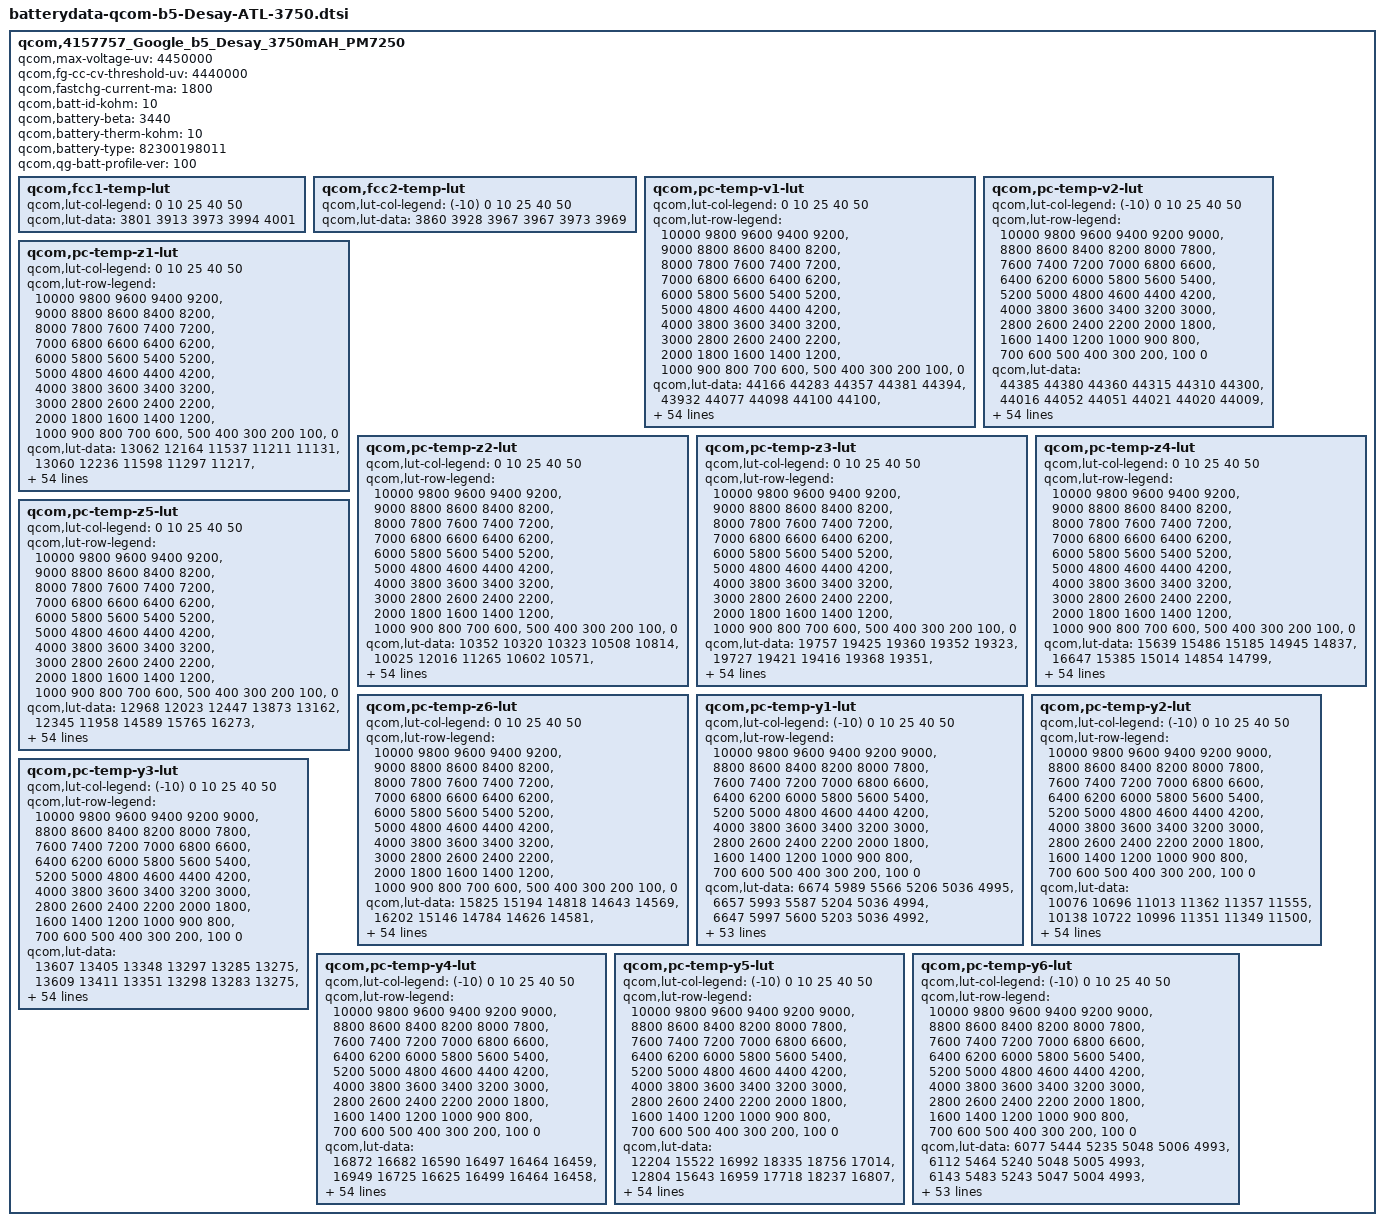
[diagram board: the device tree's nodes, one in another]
// SPDX-License-Identifier: GPL-2.0
qcom,4157757_Google_b5_Desay_3750mAH_PM7250 {
	/* Desay_3750mAH_PM7250_Sep5th2019 */
	qcom,max-voltage-uv = <4450000>;
	qcom,fg-cc-cv-threshold-uv = <4440000>;
	qcom,fastchg-current-ma = <1800>;
	qcom,batt-id-kohm = <10>;
	qcom,battery-beta = <3440>;
	qcom,battery-therm-kohm = <10>;
	qcom,battery-type = "82300198011";
	qcom,qg-batt-profile-ver = <100>;

	qcom,fcc1-temp-lut {
		qcom,lut-col-legend = <0 10 25 40 50>;
		qcom,lut-data = <3801 3913 3973 3994 4001>;
	};

	qcom,fcc2-temp-lut {
		qcom,lut-col-legend = <(-10) 0 10 25 40 50>;
		qcom,lut-data = <3860 3928 3967 3967 3973 3969>;
	};

	qcom,pc-temp-v1-lut {
		qcom,lut-col-legend = <0 10 25 40 50>;
		qcom,lut-row-legend = <10000 9800 9600 9400 9200>,
			<9000 8800 8600 8400 8200>,
			<8000 7800 7600 7400 7200>,
			<7000 6800 6600 6400 6200>,
			<6000 5800 5600 5400 5200>,
			<5000 4800 4600 4400 4200>,
			<4000 3800 3600 3400 3200>,
			<3000 2800 2600 2400 2200>,
			<2000 1800 1600 1400 1200>,
			<1000 900 800 700 600>,
			<500 400 300 200 100>,
			<0>;
		qcom,lut-data = <44166 44283 44357 44381 44394>,
			<43932 44077 44098 44100 44100>,
			<43697 43822 43870 43869 43864>,
			<43459 43586 43639 43651 43652>,
			<43219 43362 43409 43427 43436>,
			<42975 43126 43177 43197 43208>,
			<42732 42878 42935 42961 42973>,
			<42489 42629 42686 42717 42730>,
			<42247 42380 42437 42470 42483>,
			<42008 42134 42188 42220 42236>,
			<41773 41892 41942 41972 41989>,
			<41543 41654 41701 41730 41748>,
			<41318 41423 41465 41491 41512>,
			<41100 41198 41236 41260 41279>,
			<40894 40982 41014 41035 41052>,
			<40696 40779 40800 40818 40833>,
			<40493 40583 40593 40608 40621>,
			<40286 40389 40395 40406 40418>,
			<40097 40196 40209 40216 40226>,
			<39936 40012 40030 40034 40042>,
			<39786 39849 39857 39857 39863>,
			<39632 39682 39691 39688 39693>,
			<39478 39462 39493 39501 39507>,
			<39315 39201 39215 39257 39270>,
			<39129 38995 38977 39025 39038>,
			<38943 38830 38848 38869 38877>,
			<38787 38701 38750 38747 38749>,
			<38644 38612 38649 38635 38635>,
			<38537 38539 38551 38534 38531>,
			<38464 38467 38460 38440 38435>,
			<38407 38398 38377 38353 38346>,
			<38359 38334 38303 38274 38264>,
			<38318 38277 38239 38205 38191>,
			<38280 38225 38183 38143 38124>,
			<38248 38181 38134 38088 38062>,
			<38216 38142 38091 38039 38006>,
			<38185 38105 38048 37988 37946>,
			<38152 38073 38007 37932 37876>,
			<38106 38031 37958 37868 37797>,
			<38034 37950 37883 37788 37712>,
			<37942 37837 37776 37687 37616>,
			<37830 37718 37660 37574 37505>,
			<37694 37584 37526 37441 37371>,
			<37534 37421 37366 37286 37216>,
			<37376 37256 37200 37126 37058>,
			<37237 37141 37095 37028 36969>,
			<37199 37110 37063 37005 36945>,
			<37162 37089 37045 36990 36930>,
			<37128 37067 37027 36973 36913>,
			<37096 37035 36993 36935 36870>,
			<37047 36876 36814 36732 36645>,
			<36835 36460 36397 36301 36205>,
			<36374 35866 35820 35726 35629>,
			<35722 35018 35031 34942 34846>,
			<34695 33600 33805 33737 33630>,
			<30000 30000 30000 30000 30000>;
	};

	qcom,pc-temp-v2-lut {
		qcom,lut-col-legend = <(-10) 0 10 25 40 50>;
		qcom,lut-row-legend = <10000 9800 9600 9400 9200 9000>,
			<8800 8600 8400 8200 8000 7800>,
			<7600 7400 7200 7000 6800 6600>,
			<6400 6200 6000 5800 5600 5400>,
			<5200 5000 4800 4600 4400 4200>,
			<4000 3800 3600 3400 3200 3000>,
			<2800 2600 2400 2200 2000 1800>,
			<1600 1400 1200 1000 900 800>,
			<700 600 500 400 300 200>,
			<100 0>;
		qcom,lut-data = <44385 44380 44360 44315 44310 44300>,
			<44016 44052 44051 44021 44020 44009>,
			<43693 43758 43771 43750 43752 43740>,
			<43425 43507 43523 43505 43508 43496>,
			<43202 43290 43305 43283 43286 43275>,
			<42976 43064 43076 43052 43056 43046>,
			<42735 42820 42831 42808 42814 42807>,
			<42491 42572 42583 42562 42570 42565>,
			<42247 42323 42336 42314 42325 42321>,
			<42003 42073 42089 42067 42080 42076>,
			<41748 41830 41845 41824 41838 41835>,
			<41463 41593 41604 41585 41599 41596>,
			<41209 41363 41369 41352 41365 41362>,
			<41039 41139 41138 41121 41135 41134>,
			<40889 40920 40915 40897 40911 40912>,
			<40670 40714 40702 40681 40694 40697>,
			<40309 40515 40495 40474 40485 40488>,
			<39976 40290 40290 40274 40285 40287>,
			<39743 40017 40089 40084 40095 40095>,
			<39535 39748 39874 39893 39909 39909>,
			<39326 39514 39624 39703 39732 39735>,
			<39122 39298 39374 39504 39549 39555>,
			<38927 39102 39160 39274 39319 39328>,
			<38728 38921 38968 39024 39059 39070>,
			<38549 38757 38799 38832 38865 38875>,
			<38413 38609 38651 38688 38722 38731>,
			<38301 38471 38519 38564 38598 38606>,
			<38213 38337 38403 38452 38486 38493>,
			<38146 38211 38297 38351 38385 38392>,
			<38087 38109 38196 38256 38290 38296>,
			<38030 38022 38102 38169 38203 38209>,
			<37975 37952 38016 38090 38125 38130>,
			<37919 37904 37937 38019 38056 38058>,
			<37860 37863 37869 37952 37989 37988>,
			<37802 37820 37820 37889 37923 37918>,
			<37742 37776 37778 37828 37856 37844>,
			<37679 37729 37735 37761 37770 37748>,
			<37612 37679 37692 37691 37663 37623>,
			<37539 37620 37639 37615 37562 37509>,
			<37461 37540 37569 37529 37468 37413>,
			<37378 37437 37480 37441 37382 37324>,
			<37288 37334 37361 37353 37300 37238>,
			<37189 37215 37219 37221 37168 37109>,
			<37092 37072 37069 37093 37041 36982>,
			<36997 36906 36894 36928 36885 36831>,
			<36895 36788 36808 36884 36852 36803>,
			<36847 36754 36777 36871 36842 36791>,
			<36805 36717 36741 36855 36829 36776>,
			<36763 36677 36690 36828 36802 36752>,
			<36720 36631 36611 36762 36733 36666>,
			<36669 36538 36369 36523 36464 36377>,
			<36575 36271 35870 36045 35976 35873>,
			<36387 35688 35176 35397 35328 35223>,
			<36021 34813 34136 34511 34430 34317>,
			<35178 33550 32672 33199 33078 32962>,
			<34435 32158 27268 28016 28359 28215>;
	};

	qcom,pc-temp-z1-lut {
		qcom,lut-col-legend = <0 10 25 40 50>;
		qcom,lut-row-legend = <10000 9800 9600 9400 9200>,
			<9000 8800 8600 8400 8200>,
			<8000 7800 7600 7400 7200>,
			<7000 6800 6600 6400 6200>,
			<6000 5800 5600 5400 5200>,
			<5000 4800 4600 4400 4200>,
			<4000 3800 3600 3400 3200>,
			<3000 2800 2600 2400 2200>,
			<2000 1800 1600 1400 1200>,
			<1000 900 800 700 600>,
			<500 400 300 200 100>,
			<0>;
		qcom,lut-data = <13062 12164 11537 11211 11131>,
			<13060 12236 11598 11297 11217>,
			<13088 12242 11595 11304 11224>,
			<13103 12238 11586 11300 11225>,
			<13092 12230 11582 11298 11224>,
			<13074 12219 11578 11297 11225>,
			<13065 12200 11571 11295 11225>,
			<13061 12184 11563 11293 11225>,
			<13059 12171 11557 11292 11224>,
			<13060 12159 11552 11291 11223>,
			<13061 12154 11550 11291 11223>,
			<13061 12149 11550 11290 11223>,
			<13057 12148 11549 11290 11225>,
			<13050 12153 11550 11290 11226>,
			<13036 12158 11551 11291 11228>,
			<13019 12158 11552 11292 11229>,
			<13012 12157 11552 11294 11231>,
			<13013 12156 11554 11296 11233>,
			<13012 12153 11557 11299 11235>,
			<13008 12152 11562 11301 11236>,
			<13005 12159 11564 11303 11238>,
			<13006 12167 11566 11305 11241>,
			<13015 12169 11568 11307 11243>,
			<13021 12174 11571 11310 11246>,
			<13024 12179 11576 11314 11249>,
			<13026 12187 11583 11318 11252>,
			<13035 12195 11592 11322 11255>,
			<13056 12200 11600 11326 11259>,
			<13067 12205 11608 11330 11263>,
			<13075 12212 11612 11334 11266>,
			<13081 12223 11615 11337 11269>,
			<13076 12227 11617 11341 11271>,
			<13068 12226 11622 11344 11274>,
			<13064 12225 11629 11348 11278>,
			<13063 12231 11634 11352 11280>,
			<13066 12245 11639 11356 11283>,
			<13085 12253 11644 11359 11285>,
			<13121 12259 11650 11362 11288>,
			<13134 12268 11657 11366 11290>,
			<13133 12289 11663 11369 11293>,
			<13133 12317 11670 11372 11295>,
			<13145 12332 11675 11374 11297>,
			<13165 12344 11678 11376 11299>,
			<13184 12338 11682 11379 11301>,
			<13178 12333 11690 11383 11303>,
			<13199 12355 11700 11386 11305>,
			<13170 12340 11696 11386 11304>,
			<13198 12351 11703 11387 11305>,
			<13244 12338 11706 11387 11306>,
			<13250 12345 11703 11391 11307>,
			<13232 12352 11709 11396 11311>,
			<13212 12393 11720 11402 11317>,
			<13266 12404 11735 11412 11324>,
			<13282 12438 11759 11424 11335>,
			<13282 12438 11759 11424 11335>,
			<13282 12438 11759 11424 11335>;
	};

	qcom,pc-temp-z2-lut {
		qcom,lut-col-legend = <0 10 25 40 50>;
		qcom,lut-row-legend = <10000 9800 9600 9400 9200>,
			<9000 8800 8600 8400 8200>,
			<8000 7800 7600 7400 7200>,
			<7000 6800 6600 6400 6200>,
			<6000 5800 5600 5400 5200>,
			<5000 4800 4600 4400 4200>,
			<4000 3800 3600 3400 3200>,
			<3000 2800 2600 2400 2200>,
			<2000 1800 1600 1400 1200>,
			<1000 900 800 700 600>,
			<500 400 300 200 100>,
			<0>;
		qcom,lut-data = <10352 10320 10323 10508 10814>,
			<10025 12016 11265 10602 10571>,
			<10025 10344 11046 11287 10950>,
			<10037 10199 10451 11310 11426>,
			<10038 10169 10400 11211 11290>,
			<10039 10141 10374 11017 11109>,
			<10041 10112 10344 10949 11078>,
			<10043 10096 10319 10930 11101>,
			<10043 10091 10318 10888 11108>,
			<10037 10088 10352 10718 10868>,
			<10025 10097 10391 10582 10613>,
			<10016 10131 10504 10711 10763>,
			<10006 10159 10632 10955 11118>,
			<10003 10176 10644 10999 11131>,
			<10015 10198 10636 10975 10742>,
			<10033 10296 10641 10964 10528>,
			<10042 10434 10671 10994 10542>,
			<10048 10441 10695 11020 10562>,
			<10057 10352 10625 10891 10581>,
			<10077 10302 10518 10635 10609>,
			<10101 10300 10504 10589 10631>,
			<10112 10302 10504 10632 10646>,
			<10119 10310 10500 10666 10670>,
			<10126 10327 10480 10660 10761>,
			<10135 10330 10465 10644 10851>,
			<10144 10310 10484 10694 10825>,
			<10153 10293 10515 10806 10739>,
			<10162 10291 10522 10808 10681>,
			<10170 10293 10524 10667 10569>,
			<10176 10295 10516 10578 10496>,
			<10183 10301 10479 10567 10482>,
			<10190 10306 10448 10565 10479>,
			<10197 10311 10456 10578 10494>,
			<10203 10316 10478 10607 10522>,
			<10209 10324 10495 10643 10566>,
			<10214 10335 10517 10693 10667>,
			<10221 10343 10536 10741 10769>,
			<10230 10348 10548 10777 10862>,
			<10242 10355 10560 10811 10932>,
			<10258 10372 10585 10854 10940>,
			<10277 10391 10618 10904 10935>,
			<10296 10397 10625 10915 10916>,
			<10320 10398 10620 10902 10841>,
			<10374 10411 10622 10891 10816>,
			<10400 10495 10646 10871 10829>,
			<10696 10700 10740 10835 10867>,
			<10622 10740 10723 10810 10840>,
			<10516 11093 10721 10793 10808>,
			<10452 11785 10721 10790 10828>,
			<10388 11976 10739 10857 10947>,
			<10368 11692 10927 10799 10746>,
			<10329 11515 11056 10697 10585>,
			<10130 11188 11035 10615 10523>,
			<10142 10535 10919 10537 10472>,
			<10142 10535 10919 10537 10472>,
			<10142 10535 10919 10537 10472>;
	};

	qcom,pc-temp-z3-lut {
		qcom,lut-col-legend = <0 10 25 40 50>;
		qcom,lut-row-legend = <10000 9800 9600 9400 9200>,
			<9000 8800 8600 8400 8200>,
			<8000 7800 7600 7400 7200>,
			<7000 6800 6600 6400 6200>,
			<6000 5800 5600 5400 5200>,
			<5000 4800 4600 4400 4200>,
			<4000 3800 3600 3400 3200>,
			<3000 2800 2600 2400 2200>,
			<2000 1800 1600 1400 1200>,
			<1000 900 800 700 600>,
			<500 400 300 200 100>,
			<0>;
		qcom,lut-data = <19757 19425 19360 19352 19323>,
			<19727 19421 19416 19368 19351>,
			<19846 19648 19442 19380 19353>,
			<19935 19689 19509 19424 19381>,
			<19949 19698 19518 19442 19399>,
			<19953 19703 19521 19448 19405>,
			<19946 19707 19520 19446 19405>,
			<19922 19708 19517 19437 19405>,
			<19904 19702 19510 19427 19403>,
			<19906 19692 19494 19411 19390>,
			<19913 19680 19484 19399 19375>,
			<19918 19664 19492 19404 19373>,
			<19927 19649 19502 19415 19373>,
			<19931 19632 19496 19414 19370>,
			<19921 19622 19478 19403 19357>,
			<19906 19630 19469 19394 19348>,
			<19899 19645 19467 19392 19344>,
			<19891 19642 19464 19389 19341>,
			<19882 19612 19453 19379 19340>,
			<19865 19597 19440 19365 19339>,
			<19848 19598 19440 19361 19339>,
			<19844 19600 19443 19364 19339>,
			<19846 19611 19446 19365 19338>,
			<19850 19637 19451 19358 19337>,
			<19855 19644 19455 19351 19337>,
			<19859 19634 19444 19367 19353>,
			<19860 19623 19426 19403 19385>,
			<19860 19614 19430 19413 19392>,
			<19858 19605 19456 19411 19383>,
			<19851 19605 19472 19407 19374>,
			<19842 19612 19477 19402 19368>,
			<19834 19616 19478 19396 19362>,
			<19827 19617 19474 19389 19357>,
			<19819 19618 19467 19382 19352>,
			<19812 19617 19462 19377 19348>,
			<19806 19614 19458 19373 19345>,
			<19800 19610 19454 19371 19343>,
			<19794 19604 19453 19371 19345>,
			<19786 19599 19451 19371 19347>,
			<19777 19595 19447 19370 19348>,
			<19766 19591 19442 19368 19347>,
			<19753 19585 19436 19367 19346>,
			<19735 19577 19431 19363 19342>,
			<19710 19567 19429 19362 19341>,
			<19577 19542 19425 19361 19343>,
			<19438 19490 19400 19348 19328>,
			<19304 19474 19401 19344 19325>,
			<19282 19404 19394 19339 19325>,
			<19280 19317 19389 19338 19323>,
			<19279 19296 19387 19334 19317>,
			<19277 19309 19366 19344 19338>,
			<19278 19314 19345 19355 19347>,
			<19282 19314 19339 19360 19349>,
			<19320 19489 19343 19362 19342>,
			<19320 19489 19343 19362 19342>,
			<19320 19489 19343 19362 19342>;
	};

	qcom,pc-temp-z4-lut {
		qcom,lut-col-legend = <0 10 25 40 50>;
		qcom,lut-row-legend = <10000 9800 9600 9400 9200>,
			<9000 8800 8600 8400 8200>,
			<8000 7800 7600 7400 7200>,
			<7000 6800 6600 6400 6200>,
			<6000 5800 5600 5400 5200>,
			<5000 4800 4600 4400 4200>,
			<4000 3800 3600 3400 3200>,
			<3000 2800 2600 2400 2200>,
			<2000 1800 1600 1400 1200>,
			<1000 900 800 700 600>,
			<500 400 300 200 100>,
			<0>;
		qcom,lut-data = <15639 15486 15185 14945 14837>,
			<16647 15385 15014 14854 14799>,
			<16403 15501 14912 14787 14754>,
			<16089 15459 15047 14843 14781>,
			<15870 15264 14991 14831 14792>,
			<15675 15140 14912 14785 14760>,
			<15534 15057 14867 14759 14736>,
			<15433 14995 14832 14741 14715>,
			<15346 14948 14809 14732 14706>,
			<15261 14911 14795 14737 14713>,
			<15181 14877 14780 14743 14721>,
			<15112 14847 14748 14725 14713>,
			<15048 14833 14720 14695 14697>,
			<14993 14828 14719 14688 14693>,
			<14945 14822 14722 14687 14699>,
			<14906 14792 14722 14685 14701>,
			<14890 14749 14714 14678 14695>,
			<14882 14747 14706 14671 14688>,
			<14875 14773 14711 14674 14681>,
			<14865 14787 14720 14685 14674>,
			<14853 14774 14721 14689 14673>,
			<14840 14758 14721 14692 14677>,
			<14820 14777 14728 14697 14685>,
			<14812 14835 14814 14771 14743>,
			<14840 14873 14884 14846 14805>,
			<14880 14905 14883 14829 14790>,
			<14905 14924 14879 14777 14739>,
			<14935 14914 14863 14748 14719>,
			<14947 14891 14815 14732 14713>,
			<14940 14869 14780 14721 14708>,
			<14928 14847 14760 14712 14701>,
			<14916 14828 14747 14706 14694>,
			<14899 14814 14742 14701 14687>,
			<14882 14802 14740 14698 14681>,
			<14867 14795 14739 14698 14680>,
			<14853 14789 14739 14699 14682>,
			<14837 14784 14739 14701 14685>,
			<14822 14778 14740 14708 14696>,
			<14808 14774 14743 14716 14707>,
			<14795 14772 14746 14719 14707>,
			<14784 14770 14750 14720 14703>,
			<14771 14763 14748 14719 14699>,
			<14758 14743 14732 14709 14692>,
			<14741 14728 14722 14705 14691>,
			<14785 14709 14713 14702 14692>,
			<14853 14683 14682 14680 14675>,
			<14996 14692 14670 14675 14668>,
			<15014 14757 14662 14660 14650>,
			<15009 14847 14652 14643 14635>,
			<15004 14865 14650 14644 14638>,
			<14999 14857 14688 14653 14636>,
			<15003 14864 14720 14649 14633>,
			<15025 14876 14729 14644 14632>,
			<15015 14703 14729 14642 14638>,
			<15015 14703 14729 14642 14638>,
			<15015 14703 14729 14642 14638>;
	};

	qcom,pc-temp-z5-lut {
		qcom,lut-col-legend = <0 10 25 40 50>;
		qcom,lut-row-legend = <10000 9800 9600 9400 9200>,
			<9000 8800 8600 8400 8200>,
			<8000 7800 7600 7400 7200>,
			<7000 6800 6600 6400 6200>,
			<6000 5800 5600 5400 5200>,
			<5000 4800 4600 4400 4200>,
			<4000 3800 3600 3400 3200>,
			<3000 2800 2600 2400 2200>,
			<2000 1800 1600 1400 1200>,
			<1000 900 800 700 600>,
			<500 400 300 200 100>,
			<0>;
		qcom,lut-data = <12968 12023 12447 13873 13162>,
			<12345 11958 14589 15765 16273>,
			<12974 14415 16140 17362 17820>,
			<13597 14919 16270 17877 18335>,
			<13932 15276 16688 18411 18110>,
			<14183 15699 17094 19680 19215>,
			<14351 16216 17530 20303 20468>,
			<14451 16681 17968 20664 22319>,
			<14592 17020 18188 20713 23102>,
			<14947 17367 18274 19475 21255>,
			<15528 17981 18432 18371 19249>,
			<16192 18817 21047 20691 19842>,
			<17077 19082 24258 24989 21496>,
			<18042 19005 23944 25496 21523>,
			<18997 18947 22318 24141 19427>,
			<19977 20520 21913 23534 18182>,
			<20982 23291 22886 24902 18258>,
			<22085 23434 23735 26324 18571>,
			<22762 21584 22973 24754 19267>,
			<22501 20616 21751 21323 20410>,
			<22042 22279 22426 20921 21078>,
			<23087 25591 24458 22039 21594>,
			<27100 31519 25610 22521 21616>,
			<31307 40467 26065 19709 18897>,
			<35465 42580 26084 16726 15878>,
			<39100 36316 22963 17180 16651>,
			<40628 29846 18048 18694 19163>,
			<40842 26487 17669 19716 20211>,
			<39943 23903 19501 20581 20347>,
			<37932 23741 21475 21523 20330>,
			<35923 24852 24281 22689 20802>,
			<34782 26123 27096 23914 21651>,
			<33732 28095 28889 24978 22584>,
			<32866 30303 30365 25956 23880>,
			<32368 31995 31438 26830 25018>,
			<32324 33449 32524 27864 26248>,
			<32730 33717 32959 28349 26845>,
			<33387 33133 32742 27942 26478>,
			<34232 32708 32265 27191 25783>,
			<35643 32862 30733 25989 24978>,
			<36665 33090 27915 23977 23810>,
			<35896 32737 26595 23033 22835>,
			<34298 31438 26070 22572 22057>,
			<33123 30963 25853 22182 21399>,
			<26641 30387 25646 21413 20718>,
			<19028 28698 25046 21574 19399>,
			<12237 23877 26575 21147 19410>,
			<11614 16410 25301 21819 21994>,
			<11571 12483 24631 24825 25933>,
			<11548 11904 24449 23281 23662>,
			<11541 12201 17750 20855 26002>,
			<11596 12165 14466 21917 27686>,
			<11518 12064 13895 22968 27956>,
			<11756 23977 13859 23266 21994>,
			<11756 23977 13859 23266 21994>,
			<11756 23977 13859 23266 21994>;
	};

	qcom,pc-temp-z6-lut {
		qcom,lut-col-legend = <0 10 25 40 50>;
		qcom,lut-row-legend = <10000 9800 9600 9400 9200>,
			<9000 8800 8600 8400 8200>,
			<8000 7800 7600 7400 7200>,
			<7000 6800 6600 6400 6200>,
			<6000 5800 5600 5400 5200>,
			<5000 4800 4600 4400 4200>,
			<4000 3800 3600 3400 3200>,
			<3000 2800 2600 2400 2200>,
			<2000 1800 1600 1400 1200>,
			<1000 900 800 700 600>,
			<500 400 300 200 100>,
			<0>;
		qcom,lut-data = <15825 15194 14818 14643 14569>,
			<16202 15146 14784 14626 14581>,
			<16127 15293 14752 14606 14564>,
			<16020 15284 14839 14654 14592>,
			<15921 15196 14817 14655 14604>,
			<15817 15138 14785 14641 14595>,
			<15733 15098 14764 14629 14587>,
			<15665 15064 14746 14616 14579>,
			<15608 15035 14729 14606 14572>,
			<15562 15010 14714 14600 14567>,
			<15524 14985 14702 14595 14563>,
			<15490 14962 14694 14590 14558>,
			<15461 14946 14687 14584 14553>,
			<15433 14936 14681 14578 14548>,
			<15402 14927 14674 14572 14543>,
			<15374 14917 14669 14567 14539>,
			<15360 14908 14664 14563 14534>,
			<15353 14903 14660 14559 14530>,
			<15346 14900 14656 14555 14526>,
			<15335 14897 14654 14552 14523>,
			<15323 14893 14654 14552 14523>,
			<15318 14890 14656 14554 14525>,
			<15314 14904 14662 14558 14528>,
			<15313 14945 14703 14588 14554>,
			<15330 14966 14736 14617 14582>,
			<15354 14977 14732 14618 14583>,
			<15367 14982 14724 14615 14580>,
			<15382 14974 14718 14611 14576>,
			<15388 14962 14713 14603 14569>,
			<15383 14955 14708 14596 14562>,
			<15375 14950 14703 14590 14556>,
			<15367 14946 14699 14585 14550>,
			<15357 14942 14695 14579 14545>,
			<15349 14939 14691 14575 14539>,
			<15342 14937 14689 14572 14537>,
			<15336 14935 14687 14571 14537>,
			<15330 14933 14687 14570 14537>,
			<15326 14931 14688 14573 14542>,
			<15322 14930 14689 14578 14548>,
			<15321 14932 14689 14578 14549>,
			<15319 14935 14689 14578 14547>,
			<15315 14933 14688 14578 14545>,
			<15310 14925 14680 14572 14540>,
			<15302 14918 14676 14570 14540>,
			<15267 14905 14672 14569 14542>,
			<15232 14872 14649 14553 14527>,
			<15228 14868 14645 14549 14522>,
			<15227 14861 14638 14540 14514>,
			<15227 14857 14632 14532 14506>,
			<15227 14857 14631 14531 14505>,
			<15233 14865 14640 14541 14516>,
			<15246 14877 14646 14546 14521>,
			<15272 14891 14650 14549 14524>,
			<15306 14921 14658 14552 14525>,
			<15306 14921 14658 14552 14525>,
			<15306 14921 14658 14552 14525>;
	};

	qcom,pc-temp-y1-lut {
		qcom,lut-col-legend = <(-10) 0 10 25 40 50>;
		qcom,lut-row-legend = <10000 9800 9600 9400 9200 9000>,
			<8800 8600 8400 8200 8000 7800>,
			<7600 7400 7200 7000 6800 6600>,
			<6400 6200 6000 5800 5600 5400>,
			<5200 5000 4800 4600 4400 4200>,
			<4000 3800 3600 3400 3200 3000>,
			<2800 2600 2400 2200 2000 1800>,
			<1600 1400 1200 1000 900 800>,
			<700 600 500 400 300 200>,
			<100 0>;
		qcom,lut-data = <6674 5989 5566 5206 5036 4995>,
			<6657 5993 5587 5204 5036 4994>,
			<6647 5997 5600 5203 5036 4992>,
			<6641 6002 5608 5201 5035 4990>,
			<6639 6004 5612 5199 5034 4988>,
			<6639 6003 5612 5197 5033 4988>,
			<6644 6000 5601 5196 5031 4988>,
			<6650 5996 5592 5194 5030 4988>,
			<6656 5989 5593 5191 5029 4988>,
			<6669 5980 5595 5187 5028 4986>,
			<6672 5979 5593 5185 5028 4986>,
			<6666 5985 5586 5182 5027 4987>,
			<6656 5992 5579 5181 5026 4988>,
			<6648 6011 5574 5182 5026 4988>,
			<6640 6031 5571 5183 5026 4988>,
			<6640 6025 5574 5182 5027 4989>,
			<6650 6003 5580 5182 5028 4989>,
			<6658 5995 5582 5182 5029 4990>,
			<6656 6000 5580 5184 5030 4991>,
			<6652 6005 5579 5186 5031 4991>,
			<6653 6008 5581 5189 5032 4992>,
			<6653 6010 5584 5191 5032 4992>,
			<6653 6014 5585 5194 5033 4993>,
			<6651 6022 5588 5197 5034 4995>,
			<6646 6030 5591 5200 5036 4996>,
			<6645 6035 5593 5203 5038 4998>,
			<6649 6037 5595 5207 5040 4999>,
			<6656 6034 5597 5210 5041 5001>,
			<6678 6030 5599 5214 5043 5002>,
			<6701 6029 5599 5218 5045 5003>,
			<6701 6026 5600 5223 5049 5005>,
			<6689 6024 5601 5227 5052 5006>,
			<6678 6026 5603 5230 5054 5009>,
			<6648 6031 5607 5233 5056 5011>,
			<6630 6033 5619 5237 5058 5013>,
			<6636 6035 5635 5242 5060 5015>,
			<6647 6036 5635 5246 5062 5017>,
			<6657 6037 5628 5249 5064 5018>,
			<6668 6038 5626 5251 5066 5019>,
			<6675 6050 5631 5255 5067 5020>,
			<6686 6070 5638 5256 5068 5021>,
			<6695 6057 5648 5252 5071 5022>,
			<6689 6072 5634 5267 5072 5024>,
			<6703 6077 5661 5267 5073 5025>,
			<6726 6086 5656 5270 5076 5027>,
			<6720 6063 5676 5265 5077 5027>,
			<6752 6080 5669 5269 5077 5028>,
			<6735 6093 5659 5273 5079 5028>,
			<6782 6131 5663 5274 5080 5029>,
			<6823 6112 5663 5278 5080 5030>,
			<6818 6144 5679 5284 5080 5030>,
			<6955 6223 5710 5295 5085 5034>,
			<7106 6341 5799 5308 5091 5039>,
			<7298 6589 5946 5324 5098 5045>,
			<7298 6589 5946 5324 5098 5045>,
			<7298 6589 5946 5324 5098 5045>;
	};

	qcom,pc-temp-y2-lut {
		qcom,lut-col-legend = <(-10) 0 10 25 40 50>;
		qcom,lut-row-legend = <10000 9800 9600 9400 9200 9000>,
			<8800 8600 8400 8200 8000 7800>,
			<7600 7400 7200 7000 6800 6600>,
			<6400 6200 6000 5800 5600 5400>,
			<5200 5000 4800 4600 4400 4200>,
			<4000 3800 3600 3400 3200 3000>,
			<2800 2600 2400 2200 2000 1800>,
			<1600 1400 1200 1000 900 800>,
			<700 600 500 400 300 200>,
			<100 0>;
		qcom,lut-data = <10076 10696 11013 11362 11357 11555>,
			<10138 10722 10996 11351 11349 11500>,
			<10210 10735 10977 11327 11336 11412>,
			<10281 10738 10954 11295 11321 11317>,
			<10340 10735 10930 11260 11306 11244>,
			<10374 10728 10903 11227 11291 11216>,
			<10393 10710 10870 11185 11263 11207>,
			<10405 10692 10841 11150 11236 11200>,
			<10410 10684 10819 11136 11209 11177>,
			<10411 10679 10803 11124 11176 11139>,
			<10400 10679 10798 11107 11162 11114>,
			<10280 10688 10796 11083 11149 11078>,
			<10183 10702 10796 11068 11145 11065>,
			<10293 10747 10812 11061 11163 11117>,
			<10504 10799 10841 11057 11183 11174>,
			<10517 10814 10879 11065 11190 11192>,
			<10317 10822 10930 11088 11201 11208>,
			<10194 10836 10974 11121 11215 11211>,
			<10198 10872 11019 11181 11238 11208>,
			<10200 10901 11040 11236 11275 11209>,
			<10201 10907 11037 11284 11395 11294>,
			<10199 10911 11034 11316 11508 11397>,
			<10194 10919 11041 11312 11492 11404>,
			<9978 10935 11057 11298 11440 11380>,
			<9713 10946 11073 11298 11429 11386>,
			<9679 10954 11091 11327 11452 11422>,
			<9673 10960 11104 11348 11478 11455>,
			<9670 10960 11111 11349 11499 11486>,
			<9668 10956 11116 11348 11521 11512>,
			<9667 10959 11122 11354 11540 11537>,
			<9665 11004 11128 11370 11558 11608>,
			<9664 11041 11130 11376 11592 11645>,
			<9663 11002 11125 11376 11690 11667>,
			<9661 10911 11118 11372 11756 11692>,
			<9660 10730 11107 11357 11719 11740>,
			<9659 10406 11089 11336 11650 11795>,
			<9659 10256 11065 11332 11599 11768>,
			<9658 10206 11027 11332 11548 11629>,
			<9658 10157 10981 11333 11520 11563>,
			<9657 9981 10920 11338 11497 11566>,
			<9657 9704 10852 11337 11491 11561>,
			<9657 9679 10781 11324 11499 11533>,
			<9657 9672 10693 11322 11522 11587>,
			<9657 9673 10716 11320 11577 11547>,
			<9656 9666 10598 11276 11504 11536>,
			<9656 9661 10231 11196 11399 11353>,
			<9655 9659 10131 11192 11406 11291>,
			<9655 9657 9989 11197 11332 11264>,
			<9654 9656 9781 11177 11292 11235>,
			<9653 9654 9698 11141 11292 11205>,
			<9650 9652 9665 11105 11269 11204>,
			<9649 9649 9655 11056 11237 11162>,
			<9648 9648 9650 10957 11164 11079>,
			<9647 9647 9649 10848 11057 10918>,
			<9647 9647 9649 10848 11057 10918>,
			<9647 9647 9649 10848 11057 10918>;
	};

	qcom,pc-temp-y3-lut {
		qcom,lut-col-legend = <(-10) 0 10 25 40 50>;
		qcom,lut-row-legend = <10000 9800 9600 9400 9200 9000>,
			<8800 8600 8400 8200 8000 7800>,
			<7600 7400 7200 7000 6800 6600>,
			<6400 6200 6000 5800 5600 5400>,
			<5200 5000 4800 4600 4400 4200>,
			<4000 3800 3600 3400 3200 3000>,
			<2800 2600 2400 2200 2000 1800>,
			<1600 1400 1200 1000 900 800>,
			<700 600 500 400 300 200>,
			<100 0>;
		qcom,lut-data = <13607 13405 13348 13297 13285 13275>,
			<13609 13411 13351 13298 13283 13275>,
			<13612 13418 13354 13297 13281 13275>,
			<13617 13425 13356 13297 13280 13275>,
			<13620 13430 13359 13296 13279 13276>,
			<13621 13433 13360 13295 13279 13276>,
			<13621 13436 13361 13295 13280 13277>,
			<13621 13437 13361 13294 13281 13278>,
			<13618 13437 13363 13294 13283 13279>,
			<13609 13437 13366 13295 13286 13279>,
			<13602 13435 13367 13298 13287 13280>,
			<13582 13431 13367 13304 13290 13280>,
			<13567 13429 13368 13307 13291 13281>,
			<13553 13429 13367 13307 13291 13285>,
			<13525 13429 13366 13307 13292 13288>,
			<13517 13427 13364 13308 13291 13288>,
			<13519 13419 13359 13312 13289 13288>,
			<13520 13413 13359 13312 13289 13287>,
			<13516 13409 13361 13311 13292 13285>,
			<13508 13406 13362 13310 13294 13284>,
			<13500 13399 13357 13312 13295 13287>,
			<13490 13392 13348 13313 13296 13290>,
			<13483 13386 13344 13311 13293 13288>,
			<13480 13382 13340 13303 13285 13280>,
			<13477 13378 13337 13298 13282 13277>,
			<13475 13375 13334 13296 13282 13275>,
			<13476 13372 13332 13295 13281 13275>,
			<13483 13367 13332 13296 13281 13275>,
			<13505 13362 13332 13296 13281 13275>,
			<13536 13355 13332 13296 13280 13275>,
			<13569 13342 13330 13296 13279 13275>,
			<13611 13333 13329 13297 13279 13275>,
			<13659 13339 13329 13297 13280 13275>,
			<13718 13350 13329 13297 13281 13275>,
			<13786 13359 13329 13298 13282 13276>,
			<13865 13367 13330 13298 13282 13277>,
			<13951 13377 13332 13298 13282 13277>,
			<14037 13393 13336 13297 13281 13275>,
			<14126 13413 13339 13296 13280 13275>,
			<14204 13433 13343 13294 13278 13274>,
			<14268 13457 13345 13292 13278 13274>,
			<14321 13494 13347 13294 13280 13274>,
			<14365 13533 13348 13293 13277 13274>,
			<14407 13508 13342 13292 13277 13275>,
			<14348 13582 13349 13294 13276 13273>,
			<14514 13724 13353 13296 13278 13276>,
			<14622 13837 13368 13299 13280 13277>,
			<14761 13983 13387 13303 13284 13280>,
			<14961 14207 13419 13306 13287 13284>,
			<15338 14564 13497 13310 13291 13284>,
			<16612 15272 13658 13310 13287 13282>,
			<20476 18407 14204 13312 13289 13281>,
			<31819 31860 16531 13318 13291 13285>,
			<65535 65535 30317 13328 13294 13287>,
			<65535 65535 30317 13328 13294 13287>,
			<65535 65535 30317 13328 13294 13287>;
	};

	qcom,pc-temp-y4-lut {
		qcom,lut-col-legend = <(-10) 0 10 25 40 50>;
		qcom,lut-row-legend = <10000 9800 9600 9400 9200 9000>,
			<8800 8600 8400 8200 8000 7800>,
			<7600 7400 7200 7000 6800 6600>,
			<6400 6200 6000 5800 5600 5400>,
			<5200 5000 4800 4600 4400 4200>,
			<4000 3800 3600 3400 3200 3000>,
			<2800 2600 2400 2200 2000 1800>,
			<1600 1400 1200 1000 900 800>,
			<700 600 500 400 300 200>,
			<100 0>;
		qcom,lut-data = <16872 16682 16590 16497 16464 16459>,
			<16949 16725 16625 16499 16464 16458>,
			<17093 16796 16657 16500 16465 16457>,
			<17252 16871 16683 16502 16466 16455>,
			<17377 16928 16699 16504 16466 16454>,
			<17419 16943 16702 16506 16467 16453>,
			<17412 16938 16692 16510 16467 16453>,
			<17403 16931 16682 16515 16467 16452>,
			<17398 16928 16677 16519 16467 16453>,
			<17395 16926 16674 16523 16467 16456>,
			<17396 16928 16675 16523 16468 16459>,
			<17414 16947 16683 16521 16469 16463>,
			<17435 16971 16693 16521 16472 16465>,
			<17483 16994 16709 16531 16477 16464>,
			<17562 17019 16731 16546 16484 16464>,
			<17552 17048 16772 16558 16494 16467>,
			<17354 17083 16823 16570 16507 16476>,
			<17182 17086 16834 16591 16519 16487>,
			<17123 16982 16830 16630 16531 16501>,
			<17080 16871 16821 16655 16546 16517>,
			<17031 16822 16768 16662 16577 16540>,
			<16979 16785 16693 16666 16603 16557>,
			<16935 16752 16647 16631 16575 16538>,
			<16894 16722 16610 16538 16505 16486>,
			<16865 16696 16590 16503 16477 16466>,
			<16855 16674 16577 16496 16469 16461>,
			<16849 16654 16570 16493 16466 16459>,
			<16847 16626 16567 16495 16468 16461>,
			<16847 16597 16564 16499 16473 16464>,
			<16849 16592 16560 16504 16479 16469>,
			<16852 16605 16554 16510 16488 16476>,
			<16856 16618 16547 16516 16498 16484>,
			<16862 16621 16533 16525 16508 16495>,
			<16872 16625 16524 16531 16516 16503>,
			<16880 16641 16530 16531 16521 16506>,
			<16885 16681 16544 16531 16525 16508>,
			<16890 16714 16561 16528 16517 16503>,
			<16893 16740 16584 16512 16488 16478>,
			<16896 16763 16607 16498 16469 16463>,
			<16897 16785 16629 16486 16462 16457>,
			<16892 16803 16639 16484 16461 16456>,
			<16886 16796 16643 16495 16466 16461>,
			<16882 16780 16628 16489 16461 16452>,
			<16873 16736 16591 16488 16463 16452>,
			<16840 16721 16591 16472 16448 16436>,
			<16848 16727 16636 16484 16457 16446>,
			<16858 16728 16654 16494 16465 16456>,
			<16866 16750 16686 16508 16472 16464>,
			<16880 16777 16739 16527 16486 16481>,
			<16901 16811 16794 16542 16496 16487>,
			<17006 16858 16815 16533 16469 16459>,
			<17485 17156 16839 16533 16462 16452>,
			<18953 19855 17156 16557 16473 16465>,
			<26066 65535 25613 16622 16514 16504>,
			<26066 65535 25613 16622 16514 16504>,
			<26066 65535 25613 16622 16514 16504>;
	};

	qcom,pc-temp-y5-lut {
		qcom,lut-col-legend = <(-10) 0 10 25 40 50>;
		qcom,lut-row-legend = <10000 9800 9600 9400 9200 9000>,
			<8800 8600 8400 8200 8000 7800>,
			<7600 7400 7200 7000 6800 6600>,
			<6400 6200 6000 5800 5600 5400>,
			<5200 5000 4800 4600 4400 4200>,
			<4000 3800 3600 3400 3200 3000>,
			<2800 2600 2400 2200 2000 1800>,
			<1600 1400 1200 1000 900 800>,
			<700 600 500 400 300 200>,
			<100 0>;
		qcom,lut-data = <12204 15522 16992 18335 18756 17014>,
			<12804 15643 16959 17718 18237 16807>,
			<13380 15721 16877 16852 17189 16578>,
			<13920 15765 16758 15916 16012 16374>,
			<14413 15782 16617 15089 15110 16243>,
			<14849 15780 16461 14526 14846 16231>,
			<15285 15749 16253 13994 14830 16318>,
			<15617 15691 16070 13592 14814 16385>,
			<15721 15542 15957 13393 15148 16258>,
			<15717 15279 15836 13265 15741 15954>,
			<15639 15056 15618 13422 15939 15608>,
			<14964 14813 15162 14165 16312 15157>,
			<14417 14690 14771 14494 16322 15020>,
			<15123 14686 14455 14008 15854 16090>,
			<16443 14694 14266 13527 15245 17150>,
			<16669 15252 14295 13547 14511 16844>,
			<16548 16911 14417 13635 13773 15931>,
			<16575 17899 14953 13667 13639 15046>,
			<16505 18518 17243 13615 13709 14039>,
			<16335 18929 18920 13680 13844 13605>,
			<16286 19031 19515 16240 14605 14268>,
			<16273 19101 19871 19189 15731 15375>,
			<16118 19239 19988 19355 16731 16440>,
			<14779 19472 20060 19228 17700 17521>,
			<13049 19682 20031 19006 18140 17710>,
			<12268 19905 19671 18445 18403 17124>,
			<11752 20107 19424 18074 18512 16584>,
			<11602 19674 19879 18203 18181 16398>,
			<11659 18467 20592 18463 17551 16336>,
			<11739 17501 20847 18590 16841 16223>,
			<11816 14941 20918 18660 16008 15878>,
			<11930 13041 20892 18795 15810 15754>,
			<12015 13534 20795 19250 16266 15747>,
			<12070 14396 20626 19842 16946 15811>,
			<12144 14639 20058 20592 17960 16489>,
			<12345 14493 19252 21367 19050 17579>,
			<12585 14666 18980 21558 19450 18089>,
			<12706 15149 18871 21411 19648 18420>,
			<12820 15519 18720 20997 19692 18509>,
			<12888 14859 18183 18880 18644 18224>,
			<12875 13406 17581 17469 18318 17710>,
			<12778 13326 17049 17164 18454 16860>,
			<12373 13265 16819 16940 16525 16968>,
			<12141 12685 16920 16850 15948 17379>,
			<11887 12606 16922 18811 17189 19807>,
			<11747 12354 15049 18136 16311 18038>,
			<11681 12627 14634 18278 16137 15994>,
			<11775 12366 14013 17772 16589 16711>,
			<11790 12282 12904 16602 16298 17913>,
			<11841 12513 12907 16587 17547 17133>,
			<11664 12492 12838 17922 18904 18810>,
			<10693 11485 12670 19741 21243 19481>,
			<9758 9642 11552 19715 21716 21752>,
			<9255 8934 9290 20172 22210 22483>,
			<9255 8934 9290 20172 22210 22483>,
			<9255 8934 9290 20172 22210 22483>;
	};

	qcom,pc-temp-y6-lut {
		qcom,lut-col-legend = <(-10) 0 10 25 40 50>;
		qcom,lut-row-legend = <10000 9800 9600 9400 9200 9000>,
			<8800 8600 8400 8200 8000 7800>,
			<7600 7400 7200 7000 6800 6600>,
			<6400 6200 6000 5800 5600 5400>,
			<5200 5000 4800 4600 4400 4200>,
			<4000 3800 3600 3400 3200 3000>,
			<2800 2600 2400 2200 2000 1800>,
			<1600 1400 1200 1000 900 800>,
			<700 600 500 400 300 200>,
			<100 0>;
		qcom,lut-data = <6077 5444 5235 5048 5006 4993>,
			<6112 5464 5240 5048 5005 4993>,
			<6143 5483 5243 5047 5004 4993>,
			<6166 5498 5244 5047 5003 4993>,
			<6181 5507 5244 5046 5003 4993>,
			<6186 5509 5244 5046 5004 4993>,
			<6178 5505 5238 5047 5004 4994>,
			<6166 5498 5231 5047 5005 4994>,
			<6156 5492 5228 5048 5006 4995>,
			<6145 5487 5226 5050 5008 4996>,
			<6134 5486 5226 5051 5009 4997>,
			<6113 5486 5226 5054 5011 4999>,
			<6098 5487 5227 5057 5013 5000>,
			<6110 5491 5229 5060 5015 5002>,
			<6133 5498 5234 5063 5017 5005>,
			<6128 5504 5242 5068 5020 5007>,
			<6066 5511 5253 5074 5022 5009>,
			<6018 5510 5256 5081 5026 5011>,
			<6003 5480 5256 5091 5031 5014>,
			<5990 5446 5254 5097 5037 5018>,
			<5981 5429 5235 5101 5046 5026>,
			<5971 5415 5209 5103 5054 5033>,
			<5963 5405 5193 5091 5044 5026>,
			<5953 5398 5181 5059 5018 5005>,
			<5944 5393 5174 5046 5008 4997>,
			<5947 5392 5171 5043 5005 4994>,
			<5961 5390 5169 5042 5004 4994>,
			<5979 5387 5170 5043 5005 4994>,
			<6008 5384 5172 5045 5006 4996>,
			<6045 5383 5172 5047 5008 4997>,
			<6084 5388 5172 5049 5010 4999>,
			<6128 5395 5172 5052 5013 5002>,
			<6178 5410 5172 5056 5016 5005>,
			<6233 5435 5172 5059 5020 5008>,
			<6294 5464 5176 5060 5022 5009>,
			<6364 5498 5184 5061 5024 5010>,
			<6437 5539 5195 5060 5022 5009>,
			<6508 5588 5210 5056 5013 5001>,
			<6579 5641 5227 5052 5006 4996>,
			<6640 5691 5246 5047 5003 4994>,
			<6689 5741 5266 5046 5003 4994>,
			<6732 5795 5285 5051 5007 4996>,
			<6768 5846 5295 5050 5003 4993>,
			<6806 5819 5275 5049 5004 4994>,
			<6763 5907 5305 5047 4999 4988>,
			<6905 6054 5366 5053 5004 4994>,
			<6998 6158 5411 5059 5008 4997>,
			<7115 6293 5473 5066 5013 5002>,
			<7291 6495 5563 5074 5018 5010>,
			<7625 6805 5702 5083 5024 5012>,
			<8697 7407 5914 5082 5014 5002>,
			<11774 9881 6435 5085 5013 5000>,
			<20178 20123 8374 5100 5019 5007>,
			<49567 65535 20639 5133 5034 5021>,
			<49567 65535 20639 5133 5034 5021>,
			<49567 65535 20639 5133 5034 5021>;
	};

};
